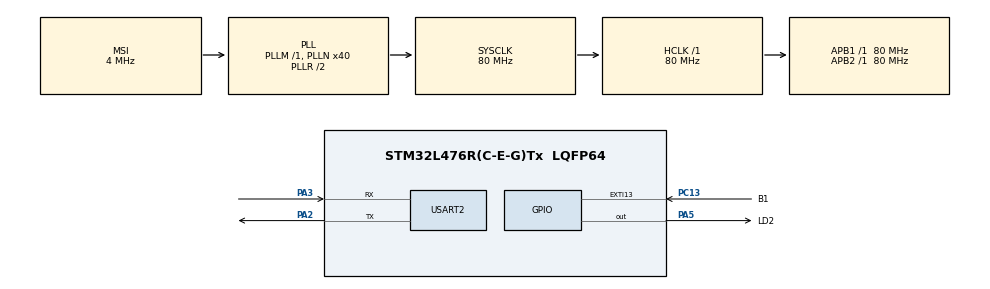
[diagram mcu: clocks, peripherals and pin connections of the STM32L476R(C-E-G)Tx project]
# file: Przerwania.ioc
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Mcu.Family=STM32L4
Mcu.Name=STM32L476R(C-E-G)Tx
Mcu.Package=LQFP64
NVIC.EXTI15_10_IRQn=true\:0\:0\:false\:false\:true\:true\:true
NVIC.PriorityGroup=NVIC_PRIORITYGROUP_4
NVIC.USART2_IRQn=true\:12\:0\:true\:false\:true\:true\:true
PA13\ (JTMS-SWDIO).Mode=Serial_Wire
PA13\ (JTMS-SWDIO).Signal=SYS_JTMS-SWDIO
PA14\ (JTCK-SWCLK).Mode=Serial_Wire
PA14\ (JTCK-SWCLK).Signal=SYS_JTCK-SWCLK
PA2.Mode=Asynchronous
PA2.Signal=USART2_TX
PA3.Mode=Asynchronous
PA3.Signal=USART2_RX
PA5.GPIO_Label=LD2
PA5.Signal=GPIO_Output
PC13.GPIO_Label=B1
PC13.Signal=GPXTI13
ProjectManager.HeapSize=0x200
ProjectManager.StackSize=0x400
ProjectManager.TargetToolchain=STM32CubeIDE
RCC.AHBFreq_Value=80000000
RCC.APB1Freq_Value=80000000
RCC.APB1TimFreq_Value=80000000
RCC.APB2Freq_Value=80000000
RCC.APB2TimFreq_Value=80000000
RCC.CortexFreq_Value=80000000
RCC.HCLKFreq_Value=80000000
RCC.HSE_VALUE=8000000
RCC.HSI_VALUE=16000000
RCC.LSE_VALUE=32768
RCC.MSI_VALUE=4000000
RCC.PLLN=40
RCC.SYSCLKFreq_VALUE=80000000
RCC.SYSCLKSource=RCC_SYSCLKSOURCE_PLLCLK
RCC.VCOOutputFreq_Value=160000000
USART2.VirtualMode-Asynchronous=VM_ASYNC
board=custom

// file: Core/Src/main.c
/* USER CODE BEGIN Header */
/**
  ******************************************************************************
  * @file           : main.c
  * @brief          : Main program body
  ******************************************************************************
  * @attention
  *
  * Copyright (c) 2021 STMicroelectronics.
  * All rights reserved.
  *
  * This software is licensed under terms that can be found in the LICENSE file
  * in the root directory of this software component.
  * If no LICENSE file comes with this software, it is provided AS-IS.
  *
  ******************************************************************************
  */
/* USER CODE END Header */
#include "main.h"
#include "usart.h"
#include "gpio.h"

/* USER CODE BEGIN Includes */
#include <stdio.h>
#include <string.h>
#define LINE_MAX_LENGTH 80
/* USER CODE END Includes */

/* USER CODE BEGIN PV */
volatile uint32_t push_counter;
/* USER CODE END PV */

void SystemClock_Config(void);

/* USER CODE BEGIN 0 */
/*
int __io_putchar(int ch)
{
	if(ch == '\n')
	{
		__io_putchar('\r');
	}

	HAL_UART_Transmit(&huart2, (uint8_t*)&ch, 1, HAL_MAX_DELAY);

	return 1;
}*/

/*void line_append(uint8_t value)
{

	if(value == '\r' || value == '\n')
	{
		if(line_length > 0)
		{
			line_buffer[line_length] = '\0';

			if(strcmp(line_buffer, 'on') == 0)
			{
				HAL_GPIO_WritePin(LD2_GPIO_Port, LD2_Pin, GPIO_PIN_SET);
			}else if(strcmp(line_buffer, 'off') == 0)
			{
				HAL_GPIO_WritePin(LD2_GPIO_Port, LD2_Pin, GPIO_PIN_RESET);
			}
			line_length = 0;
		}
	}else
	{

		if(line_length >= LINE_MAX_LENGTH)
		{
			line_length = 0;
		}
	}

	line_buffer[line_length++] = value;
}*/
/*
typedef enum
{
	MESSAGE_1,
	MESSAGE_2,
	DONE
}sender_state;

sender_state message_number = MESSAGE_1;

void send_next_message(void)
{
	static char message[] = "Hello world!\r\n";
	static char message2[] = "Witam prezesa!\r\n";

	switch(message_number)
	{
	case MESSAGE_1:

		HAL_UART_Transmit_IT(&huart2, (uint8_t*)message, strlen(message));
		message_number = MESSAGE_2;
		break;
	case MESSAGE_2:

		HAL_UART_Transmit_IT(&huart2, (uint8_t*)message2, strlen(message2));
		message_number = DONE;
		break;
	default:
		break;
	}

}*/
/* USER CODE END 0 */

int main(void)
{

  /* MCU Configuration--------------------------------------------------------*/

  /* Reset of all peripherals, Initializes the Flash interface and the Systick. */
  HAL_Init();

  /* Configure the system clock */
  SystemClock_Config();

  /* Initialize all configured peripherals */
  MX_GPIO_Init();
  MX_USART2_UART_Init();
  /* USER CODE BEGIN 2 */

  	char message[] = "Hello World!\r\n";
	HAL_UART_Transmit_IT(&huart2, (uint8_t*)message, strlen(message));

  /* USER CODE END 2 */

  /* Infinite loop */
  /* USER CODE BEGIN WHILE */

  while (1)
  {
	  /*printf("Systick = %lu\n", HAL_GetTick());*/

	/*  if(old_push_counter != push_counter)
	  {
		  printf("counter = %lu\n", push_counter);
		  old_push_counter = push_counter;
	  }*/

    /* USER CODE END WHILE */

  }
}

void SystemClock_Config(void)
{
  RCC_OscInitTypeDef RCC_OscInitStruct = {0};
  RCC_ClkInitTypeDef RCC_ClkInitStruct = {0};

  /** Configure the main internal regulator output voltage
  */
  if (HAL_PWREx_ControlVoltageScaling(PWR_REGULATOR_VOLTAGE_SCALE1) != HAL_OK)
  {
    Error_Handler();
  }
  /** Initializes the RCC Oscillators according to the specified parameters
  * in the RCC_OscInitTypeDef structure.
  */
  RCC_OscInitStruct.OscillatorType = RCC_OSCILLATORTYPE_MSI;
  RCC_OscInitStruct.MSIState = RCC_MSI_ON;
  RCC_OscInitStruct.MSICalibrationValue = 0;
  RCC_OscInitStruct.MSIClockRange = RCC_MSIRANGE_6;
  RCC_OscInitStruct.PLL.PLLState = RCC_PLL_ON;
  RCC_OscInitStruct.PLL.PLLSource = RCC_PLLSOURCE_MSI;
  RCC_OscInitStruct.PLL.PLLM = 1;
  RCC_OscInitStruct.PLL.PLLN = 40;
  RCC_OscInitStruct.PLL.PLLP = RCC_PLLP_DIV7;
  RCC_OscInitStruct.PLL.PLLQ = RCC_PLLQ_DIV2;
  RCC_OscInitStruct.PLL.PLLR = RCC_PLLR_DIV2;
  if (HAL_RCC_OscConfig(&RCC_OscInitStruct) != HAL_OK)
  {
    Error_Handler();
  }
  /** Initializes the CPU, AHB and APB buses clocks
  */
  RCC_ClkInitStruct.ClockType = RCC_CLOCKTYPE_HCLK|RCC_CLOCKTYPE_SYSCLK
                              |RCC_CLOCKTYPE_PCLK1|RCC_CLOCKTYPE_PCLK2;
  RCC_ClkInitStruct.SYSCLKSource = RCC_SYSCLKSOURCE_PLLCLK;
  RCC_ClkInitStruct.AHBCLKDivider = RCC_SYSCLK_DIV1;
  RCC_ClkInitStruct.APB1CLKDivider = RCC_HCLK_DIV1;
  RCC_ClkInitStruct.APB2CLKDivider = RCC_HCLK_DIV1;

  if (HAL_RCC_ClockConfig(&RCC_ClkInitStruct, FLASH_LATENCY_4) != HAL_OK)
  {
    Error_Handler();
  }
}

/* USER CODE BEGIN 4 */

void HAL_GPIO_EXTI_Callback(uint16_t GPIO_Pin)
{
	if(GPIO_Pin == B1_Pin)
	{
		push_counter++;
	}
}

/* USER CODE END 4 */

void Error_Handler(void)
{
  __disable_irq();
  while (1)
  {
  }
}
